# SPGSS1_1.0 register map
Vendor: Texas Instruments
Registers are 32-bit, read-write, no defined reset value unless marked. A register's access mark holds for its fields unless they carry their own. Offsets are as the file gives them; [hi:lo] are bit positions; lines under a group give offsets from that group; {n}, {i} and the like mark numbered series; 'fields as' and 'values as' point back to an identical list; <NAME> marks a mode.

## SPGSS1 (part 4 of 8)
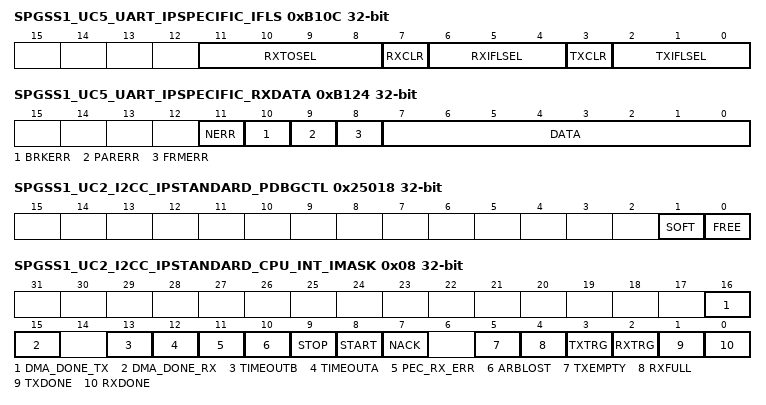
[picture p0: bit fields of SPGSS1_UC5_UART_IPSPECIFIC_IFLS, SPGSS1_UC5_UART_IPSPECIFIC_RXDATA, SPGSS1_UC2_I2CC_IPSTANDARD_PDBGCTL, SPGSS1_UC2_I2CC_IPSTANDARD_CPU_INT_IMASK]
0xB10C SPGSS1_UC5_UART_IPSPECIFIC_IFLS — UART Interrupt FIFO Level Select Register
  [11:8] RXTOSEL — UART Receive Interrupt Timeout Select. When receiving no start edge for an additional character within the set bittimes a RX interrupt is set even if the FIFO level is not reached. A value of 0 disables this function.
    0=MINIMUM (Smallest value); 15=MAXIMUM (Highest possible value)
  [7] RXCLR — RX FIFO CLEAR. Setting this bit will clear the RX FIFO contents.
    0=DISABLE (Disable FIFO clear); 1=ENABLE (Enable FIFO Clear)
  [6:4] RXIFLSEL — FIFO Level Select for generating events (interrupt/dma). Note: for undefined settings the default configuration is used.
    1=LVL_1_4 (RX FIFO >= 1/4 full); 2=LVL_1_2 (RX FIFO >= 1/2 full (default)); 3=LVL_3_4 (RX FIFO >= 3/4 full); 4=LVL_NOT_EMPTY (Opposite of empty); 5=LVL_FULL (RX FIFO is full); 6=LVL_ALMOST_FULL (RX_FIFO >= (MAX_FIFO_LEN -1)); 7=LVL_ALMOST_EMPTY (RX_FIFO <= 1)
  [3] TXCLR — TX FIFO CLEAR. Setting this bit will clear the TX FIFO contents.
    0=DISABLE (Disable FIFO clear); 1=ENABLE (Enable FIFO Clear)
  [2:0] TXIFLSEL — FIFO Level Select for generating events (interrupt/dma). Note: for undefined settings the default configuration is used.
    1=LVL_3_4 (TX FIFO <= 3/4 empty); 2=LVL_1_2 (TX FIFO <= 1/2 empty (default)); 3=LVL_1_4 (TX FIFO <= 1/4 empty); 4=LVL_NOT_FULL (Opposite of full); 5=LVL_EMPTY (TX FIFO is empty); 6=LVL_ALMOST_EMPTY (TX FIFO <= 1); 7=LVL_ALMOST_FULL (TX_FIFO >= (MAX_FIFO_LEN -1))
0xB110 SPGSS1_UC5_UART_IPSPECIFIC_IBRD — UART Integer Baud-Rate Divisor Register
  [15:0] DIVINT — Integer Baud-Rate Divisor
    0=MINIMUM (Smallest value); 0xFFFF=MAXIMUM (Highest possible value)
0xB114 SPGSS1_UC5_UART_IPSPECIFIC_FBRD — UART Fractional Baud-Rate Divisor Register
  [5:0] DIVFRAC — Fractional Baud-Rate Divisor
    0=MINIMUM (Smallest value); 63=MAXIMUM (Highest possible value)
0xB120 SPGSS1_UC5_UART_IPSPECIFIC_TXDATA — UART Transmit Data Register
  [7:0] DATA — Data Transmitted or Received Data that is to be transmitted via the UART is written to this field. When read, this field contains the data that was received by the UART.
    0=MINIMUM (Smallest value); 255=MAXIMUM (Highest possible value)
0xB124 SPGSS1_UC5_UART_IPSPECIFIC_RXDATA ro — UART Receive Data Register
  [11] NERR — Noise Error. Writing to this bit has no effect. The flag is cleared by writing 1 to the NERR bit in the UART EVENT ICLR register.
    0=CLR (No noise error occurred); 1=SET (Noise error occurred during majority voting)
  [10] BRKERR — UART Break Error Writing to this bit has no effect. The flag is cleared by writing 1 to the BRKERR bit in the UART EVENT ICLR register. This error is associated with the character at the top of the FIFO. When a break occurs, only one 0 character is loaded into the FIFO. The next character is only enabled after the receive data input goes to a 1 (marking state) and the next valid start bit is received.
    0=CLR (No break condition has occurred); 1=SET (A break condition has been detected, indicating that the receive data input was held low for longer than a full-word transmission time (defined as start, data, parity, and stop bits).)
  [9] PARERR — UART Parity Error Writing to this bit has no effect. The flag is cleared by writing 1 to the PARERR bit in the UART EVENT ICLR register.
    0=CLR (No parity error has occurred); 1=SET (The parity of the received data character does not match the parity defined by bits 2 and 7 of the UARTLCRH register.)
  [8] FRMERR — UART Framing Error Writing to this bit has no effect. The flag is cleared by writing 1 to the FRMERR bit in the UART EVENT ICLR register. This error is associated with the character at the top of the FIFO.
    0=CLR (No framing error has occurred); 1=SET (The received character does not have a valid stop bit sequence, which is one or two stop bits depending on the UARTLCRH.STP2 setting (a valid stop bit is 1).)
  [7:0] DATA — Received Data. When read, this field contains the data that was received by the UART.
    values as SPGSS1_UC5_UART_IPSPECIFIC_TXDATA.DATA
0xB148 SPGSS1_UC5_UART_IPSPECIFIC_AMASK — Self Address Mask Register
  [7:0] MSK — Self Address Mask for 9-Bit Mode This field contains the address mask that creates a set of addresses that should be matched. A 0 bit in the MSK bitfield configures, that the corresponding bit in the ADDR bitfield of the UARTxADDR register is don't care. A 1 bit in the MSK bitfield configures, that the corresponding bit in the ADDR bitfield of the UARTxADDR register must match.
    values as SPGSS1_UC5_UART_IPSPECIFIC_TXDATA.DATA
0xB14C SPGSS1_UC5_UART_IPSPECIFIC_ADDR — Self Address Register
  [7:0] ADDR — Self Address for 9-Bit Mode This field contains the address that should be matched when UARTxAMASK is FFh.
    values as SPGSS1_UC5_UART_IPSPECIFIC_TXDATA.DATA
0xBE00 SPGSS1_UC5_UART_LMGMT_DFT_ATRT_TEST0 — Test 0 register
  [4:0] DTB_MUX_SEL — This bit field is used to select DTB mux digital output signals.
    0=DISABLE (Disables DTB MUX); {v}=GRP{v} (Selects test group {v}) (v=1..7)
0x25000 SPGSS1_UC2_I2CC_IPSTANDARD_CLKDIV — Clock Divider
  [2:0] RATIO — Selects divide ratio of module clock Division factor 0 : DIV_BY_1 1 : DIV_BY_2 .... 63: DIV_BY_64
0x25008 SPGSS1_UC2_I2CC_IPSTANDARD_CLKSEL — Clock Select for Ultra Low Power peripherals
  [3] BUSCLK_SEL — Selects BUS CLK as clock source if enabled
    0=DISABLE (Does not select this clock as a source); 1=ENABLE (Select this clock as a source)
0x25018 SPGSS1_UC2_I2CC_IPSTANDARD_PDBGCTL — Peripheral Debug Control
  [1] SOFT — Soft halt boundary control. This function is only available, if [FREE] is set to 'STOP'
    0=DEPRECATED (Not supported); 1=DELAYED (The peripheral blocks the debug freeze until it has reached a boundary where it can resume without corruption)
  [0] FREE — Free run control
    0=STOP (The peripheral freezes functionality while the Core Halted input is asserted and resumes when it is deasserted.); 1=RUN (The peripheral ignores the state of the Core Halted input)
0x25020 SPGSS1_UC2_I2CC_IPSTANDARD_CPU_INT group
  0x00 SPGSS1_UC2_I2CC_IPSTANDARD_IIDX ro — Interrupt index
    [7:0] STAT — I2C Module Interrupt Vector Value. This register provides the highes priority interrupt index. A read clears the corresponding interrupt flag in RIS and MISC. 15h-1Fh = Reserved
      0=NO_INTR (No interrupt pending); 1=RXDONEFG (Data received); 2=TXDONEFG (data transmitted); 3=RXTRG (Receive Trigger); 4=TXTRG (Transmit Trigger); 5=RXFULL (RX FIFO FULL Event/interrupt pending); 6=TXEMPTY (Transmit FIFO/Buffer Empty Event/interrupt pending); 8=NACKFG (Address/Data NACK); 9=STARTFG (Start Event); 10=STOPFG (Stop Event); 11=ARBLOSTFG (Arbitration Lost); 12=PEC_RX_ERR (PEC Receive Error Event); 13=TIMEOUTA (Timeout A Event); 14=TIMEOUTB (Timeout B Event); 16=DMA_DONE_RX (DMA DONE on Channel RX); 17=DMA_DONE_TX (DMA DONE on Channel TX); 19=DMA_PREIRQ_RX (DMA PRE IRQ INTERRUPT); 20=DMA_PREIRQ_TX (DMA PRE IRQ INTERRUPT)
  0x08 SPGSS1_UC2_I2CC_IPSTANDARD_CPU_INT_IMASK — Interrupt mask
    [16] DMA_DONE_TX — DMA Done on Event Channel TX
      0=CLR (Interrupt disabled); 1=SET (Set Interrupt Mask)
    [15] DMA_DONE_RX — DMA Done on Event Channel RX
      0=CLR (Interrupt disabled); 1=SET (Set Interrupt Mask)
    [13] TIMEOUTB — Timeout B Interrupt
      0=CLR (Clear Interrupt Mask); 1=SET (Set Interrupt Mask)
    [12] TIMEOUTA — TIMEOUTA interrupt
      0=CLR (Clear Interrupt Mask); 1=SET (Set Interrupt Mask)
    [11] PEC_RX_ERR — RX Pec Error Interrupt
      0=CLR (Clear Interrupt Mask); 1=SET (Set Interrupt Mask)
    [10] ARBLOST — Arbitration Lost interrupt
      0=CLR (Clear Interrupt Mask); 1=SET (Set Interrupt Mask)
    [9] STOP — STOP interrupt
      0=CLR (Clear Interrupt Mask); 1=SET (Set Interrupt Mask)
    [8] START — START interrupt
      0=CLR (Clear Interrupt Mask); 1=SET (Set Interrupt Mask)
    [7] NACK — NACK interrupt
      0=CLR (Clear Interrupt Mask); 1=SET (Set Interrupt Mask)
    [5] TXEMPTY — Transmit FIFO/Buffer Empty interrupt.
      0=CLR (Clear Interrupt Mask); 1=SET (Set Interrupt Mask)
    [4] RXFULL — RXFIFO full event
      0=CLR (Clear Interrupt Mask); 1=SET (Set Interrupt Mask)
    [3] TXTRG — Transmit Trigger
      0=CLR (Clear Interrupt Mask); 1=SET (Set Interrupt Mask)
    [2] RXTRG — Receive Trigger
      0=CLR (Clear Interrupt Mask); 1=SET (Set Interrupt Mask)
    [1] TXDONE — Transmit Transaction completed Interrupt
      0=CLR (Clear Interrupt Mask); 1=SET (Set Interrupt Mask)
    [0] RXDONE — RXDONE interrupt
      0=CLR (Clear Interrupt Mask); 1=SET (Set Interrupt Mask)
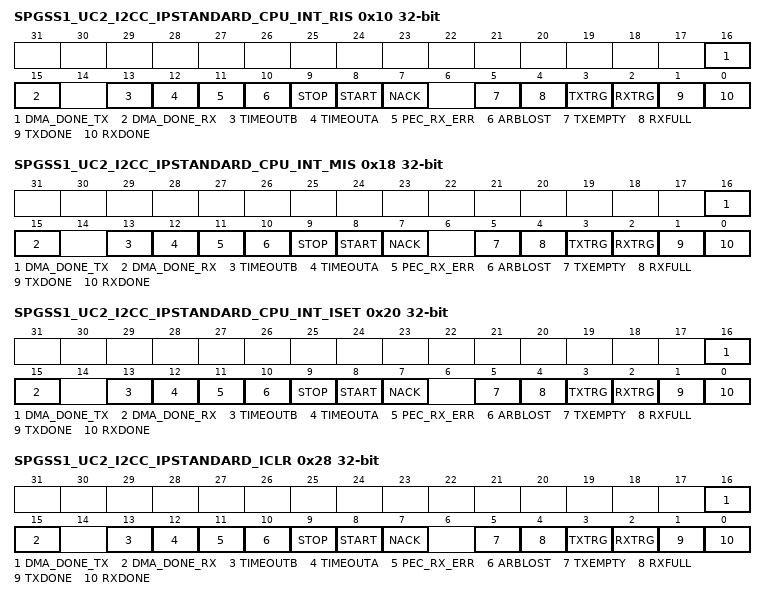
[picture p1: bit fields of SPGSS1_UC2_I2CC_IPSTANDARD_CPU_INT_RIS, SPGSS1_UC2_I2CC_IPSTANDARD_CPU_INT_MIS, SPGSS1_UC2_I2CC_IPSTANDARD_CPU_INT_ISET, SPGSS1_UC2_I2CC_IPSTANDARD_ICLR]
  0x10 SPGSS1_UC2_I2CC_IPSTANDARD_CPU_INT_RIS — Raw interrupt status
    [16] DMA_DONE_TX — DMA Done on Event Channel TX
      0=CLR (Interrupt disabled); 1=SET (Set Interrupt Mask)
    [15] DMA_DONE_RX — DMA Done on Event Channel RX
      0=CLR (Interrupt disabled); 1=SET (Set Interrupt Mask)
    [13] TIMEOUTB — Timeout B Interrupt
      0=CLR (Interrupt did not occur); 1=SET (Interrupt occured)
    [12] TIMEOUTA — Timeout A Interrupt
      0=CLR (Interrupt did not occur); 1=SET (Set Interrupt Mask)
    [11] PEC_RX_ERR — Receive PEC Error Interrupt: set when the calculated PEC does not match received PEC
      0=CLR (Interrupt did not occur); 1=SET (Interrupt Occured)
    [10] ARBLOST — Arbitration Lost Interrupt: in multi-controller systems, when this controller loses out during arbitration
      0=CLR (Interrupt did not occur); 1=SET (Set Interrupt Mask)
    [9] STOP — STOP Detection Interrupt
      0=CLR (Interrupt did not occur); 1=SET (Set Interrupt Mask)
    [8] START — START Detection Interrupt
      0=CLR (Interrupt did not occur); 1=SET (Set Interrupt Mask)
    [7] NACK — Address/Data NACK Interrupt: set when address or data nack is received
      0=CLR (Interrupt did not occur); 1=SET (Set Interrupt Mask)
    [5] TXEMPTY — Transmit FIFO Empty: set when Transmit FIFO is empty
      0=CLR (Interrupt did not occur); 1=SET (Interrupt occured)
    [4] RXFULL — RXFIFO full event. This interrupt is set when receive FIFO is full.
      0=CLR (Interrupt did not occur); 1=SET (Interrupt occured)
    [3] TXTRG — Transmit Trigger When FIFO is present, as per IFLS settings When FIFO is not present, trigger when transmit buffer is empty
      0=CLR (Clear Interrupt Mask); 1=SET (Set Interrupt Mask)
    [2] RXTRG — Receive Trigger When FIFO is present, as per IFLS settings when FIFO is not present, this indicates when buffer is full
      0=CLR (Clear Interrupt Mask); 1=SET (Set Interrupt Mask)
    [1] TXDONE — Transmit Done Interrupt: TXDONE interrupt is raised when a burst length completes Or, in case of quick command, when a quick command with R/Wn bit set to '0'
      0=CLR (Interrupt did not occur); 1=SET (Set Interrupt Mask)
    [0] RXDONE — Receive Done Interrupt: RXDONE interrupt is raised when a burst length completes Or, in case of quick command, when a quick command with R/Wn bit set to '1'
      0=CLR (Interrupt did not occur); 1=SET (Set Interrupt Mask)
  0x18 SPGSS1_UC2_I2CC_IPSTANDARD_CPU_INT_MIS — Masked interrupt status
    [16] DMA_DONE_TX — DMA Done on Event Channel TX
      0=CLR (Interrupt disabled); 1=SET (Set Interrupt Mask)
    [15] DMA_DONE_RX — DMA Done on Event Channel RX
      0=CLR (Interrupt disabled); 1=SET (Set Interrupt Mask)
    [13] TIMEOUTB — Timeout B Interrupt
      0=CLR (Clear interrupt mask); 1=SET (Set interrupt mask)
    [12] TIMEOUTA — Timeout A Interrupt
      0=CLR (Interrupt did not occur); 1=SET (Set Interrupt Mask)
    [11] PEC_RX_ERR — RX Pec Error Interrupt
      0=CLR (Clear interrupt mask); 1=SET (Set interrupt mask)
    [10] ARBLOST — Arbitration Lost Interrupt
      0=CLR (Interrupt did not occur); 1=SET (Set Interrupt Mask)
    [9] STOP — STOP Detection Interrupt
      0=CLR (Interrupt did not occur); 1=SET (Set Interrupt Mask)
    [8] START — START Detection Interrupt
      0=CLR (Interrupt did not occur); 1=SET (Set Interrupt Mask)
    [7] NACK — Address/Data NACK Interrupt
      0=CLR (Interrupt did not occur); 1=SET (Set Interrupt Mask)
    [5] TXEMPTY — Transmit FIFO Empty masked interrupt. This interrupt is set if all data in the Transmit FIFO have been shifted out and the transmit goes into idle mode.
      0=CLR (Interrupt did not occur); 1=SET (Interrupt occured)
    [4] RXFULL — Masked RXFIFO full event
      0=CLR (Interrupt did not occur); 1=SET (Interrupt occured)
    [3] TXTRG — Transmit Trigger
      0=CLR (Clear Interrupt Mask); 1=SET (Set Interrupt Mask)
    [2] RXTRG — Receive Trigger
      0=CLR (Clear Interrupt Mask); 1=SET (Set Interrupt Mask)
    [1] TXDONE — Transmit Transaction completed Interrupt
      0=CLR (Interrupt did not occur); 1=SET (Set Interrupt Mask)
    [0] RXDONE — Receive Data Interrupt
      0=CLR (Interrupt did not occur); 1=SET (Set Interrupt Mask)
  0x20 SPGSS1_UC2_I2CC_IPSTANDARD_CPU_INT_ISET — Interrupt set
    [16] DMA_DONE_TX — DMA Done on Event Channel TX
      0=NO_EFFECT (Interrupt disabled); 1=SET (Set Interrupt Mask)
    [15] DMA_DONE_RX — DMA Done on Event Channel RX
      0=NO_EFFECT (Interrupt disabled); 1=SET (Set Interrupt Mask)
    [13] TIMEOUTB — Timeout B Interrupt
      0=NO_EFFECT (Writing 0 has no effect); 1=SET (Set interrupt)
    [12] TIMEOUTA — Timeout A interrupt
      0=NO_EFFECT (Writing 0 has no effect); 1=SET (Set Interrupt Mask)
    [11] PEC_RX_ERR — RX Pec Error Interrupt
      0=NO_EFFECT (Writing 0 has no effect); 1=SET (Set interrupt)
    [10] ARBLOST — Arbitration Lost Interrupt
      values as TIMEOUTA
    [9] STOP — STOP Detection Interrupt
      values as TIMEOUTA
    [8] START — START Detection Interrupt
      values as TIMEOUTA
    [7] NACK — Address/Data NACK Interrupt
      values as TIMEOUTA
    [5] TXEMPTY — Transmit FIFO Empty interrupt mask. This interrupt is set if all data in the Transmit FIFO have been shifted out and the transmit goes into idle mode.
      0=NO_EFFECT (Writing 0 has no effect); 1=SET (Set Interrupt)
    [4] RXFULL — RXFIFO full event.
      0=NO_EFFECT (Writing 0 has no effect); 1=SET (Set Interrupt)
    [3] TXTRG — Transmit Trigger
      0=NO_EFFECT (Clear Interrupt Mask); 1=SET (Set Interrupt Mask)
    [2] RXTRG — Receive Trigger
      values as TXTRG
    [1] TXDONE — Transmit Transaction completed Interrupt
      values as TIMEOUTA
    [0] RXDONE — Receive Data Interrupt Signals that a byte has been received
      values as TIMEOUTA
  0x28 SPGSS1_UC2_I2CC_IPSTANDARD_ICLR — Interrupt clear
    [16] DMA_DONE_TX — DMA Done on Event Channel TX
      0=NO_EFFECT (Interrupt disabled); 1=CLR (Set Interrupt Mask)
    [15] DMA_DONE_RX — DMA Done on Event Channel RX
      0=NO_EFFECT (Interrupt disabled); 1=CLR (Set Interrupt Mask)
    [13] TIMEOUTB — Timeout B Interrupt
      0=NO_EFFECT (Writing 0 has no effect); 1=CLR (Clear Interrupt)
    [12] TIMEOUTA — Timeout A interrupt
      0=NO_EFFECT (Writing 0 has no effect); 1=CLR (Set Interrupt Mask)
    [11] PEC_RX_ERR — RX Pec Error Interrupt
      values as TIMEOUTB
    [10] ARBLOST — Arbitration Lost Interrupt
      values as TIMEOUTA
    [9] STOP — STOP Detection Interrupt
      values as TIMEOUTA
    [8] START — START Detection Interrupt
      values as TIMEOUTA
    [7] NACK — Address/Data NACK Interrupt
      values as TIMEOUTA
    [5] TXEMPTY — Transmit FIFO Empty interrupt mask. This interrupt is set if all data in the Transmit FIFO have been shifted out and the transmit goes into idle mode.
      values as TIMEOUTB
    [4] RXFULL — RXFIFO full event.
      values as TIMEOUTB
    [3] TXTRG — Transmit FIFO Trigger
      0=NO_EFFECT (Clear Interrupt Mask); 1=CLR (Set Interrupt Mask)
    [2] RXTRG — Receive Trigger
      values as TXTRG
    [1] TXDONE — Transmit Transaction completed Interrupt
      values as TIMEOUTA
    [0] RXDONE — Receive Data Interrupt Signals that a byte has been received
      values as TIMEOUTA
0x25050 SPGSS1_UC2_I2CC_IPSTANDARD_DMA_TRIG1 group
  0x08 SPGSS1_UC2_I2CC_IPSTANDARD_DMA_TRIG1_IMASK — Interrupt mask
    [2] RXTRG — Receive Trigger
      0=CLR (Clear Interrupt Mask); 1=SET (Set Interrupt Mask)
  0x10 SPGSS1_UC2_I2CC_IPSTANDARD_DMA_TRIG1_RIS — Raw interrupt status
    [2] RXTRG — Receive Trigger When FIFO is present, trigger when RX FIFO contains >= defined bytes when FIFO is not present, this indicates when buffer is full
      0=CLR (Clear Interrupt Mask); 1=SET (Set Interrupt Mask)
  0x18 SPGSS1_UC2_I2CC_IPSTANDARD_DMA_TRIG1_MIS — Masked interrupt status
    fields as SPGSS1_UC2_I2CC_IPSTANDARD_DMA_TRIG1.SPGSS1_UC2_I2CC_IPSTANDARD_DMA_TRIG1_IMASK
  0x20 SPGSS1_UC2_I2CC_IPSTANDARD_DMA_TRIG1_ISET — Interrupt set
    [2] RXTRG — Receive Trigger
      values as SPGSS1_UC2_I2CC_IPSTANDARD_CPU_INT.SPGSS1_UC2_I2CC_IPSTANDARD_CPU_INT_ISET.TXTRG
0x25080 SPGSS1_UC2_I2CC_IPSTANDARD_DMA_TRIG0 group
  0x08 SPGSS1_UC2_I2CC_IPSTANDARD_DMA_TRIG0_IMASK — Interrupt mask
    [3] TXTRG — Transmit Trigger
      0=CLR (Clear Interrupt Mask); 1=SET (Set Interrupt Mask)
  0x10 SPGSS1_UC2_I2CC_IPSTANDARD_DMA_TRIG0_RIS — Raw interrupt status
    fields as SPGSS1_UC2_I2CC_IPSTANDARD_DMA_TRIG0.SPGSS1_UC2_I2CC_IPSTANDARD_DMA_TRIG0_IMASK
  0x18 SPGSS1_UC2_I2CC_IPSTANDARD_DMA_TRIG0_MIS — Masked interrupt status
    fields as SPGSS1_UC2_I2CC_IPSTANDARD_DMA_TRIG0.SPGSS1_UC2_I2CC_IPSTANDARD_DMA_TRIG0_IMASK
  0x20 SPGSS1_UC2_I2CC_IPSTANDARD_DMA_TRIG0_ISET — Interrupt set
    [3] TXTRG — Transmit Trigger
      values as SPGSS1_UC2_I2CC_IPSTANDARD_CPU_INT.SPGSS1_UC2_I2CC_IPSTANDARD_CPU_INT_ISET.TXTRG
0x250E4 SPGSS1_UC2_I2CC_IPSTANDARD_INTCTL — Interrupt control register
  [0] INTEVAL — Writing a 1 to this field re-evaluates the interrupt sources.
    0=DISABLE (The interrupt or event line is disabled.); 1=EVAL (The interrupt or event line is in software mode. Software must clear the RIS.)
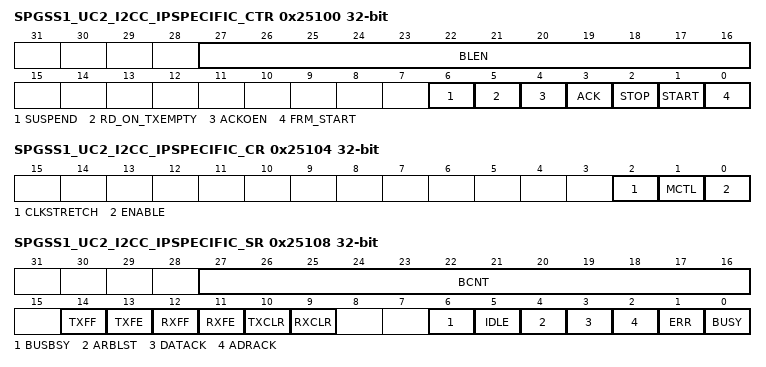
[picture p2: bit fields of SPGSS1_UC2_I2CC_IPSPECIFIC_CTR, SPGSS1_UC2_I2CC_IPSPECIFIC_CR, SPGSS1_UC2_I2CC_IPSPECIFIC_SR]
0x25100 SPGSS1_UC2_I2CC_IPSPECIFIC_CTR — Control Register
  [27:16] BLEN — I2C transaction length This field contains the programmed length of bytes of the Transaction.
    0=MINIMUM (Smallest value); 0xFFF=MAXIMUM (Highest possible value)
  [6] SUSPEND — Suspend external communication
    0=DISABLE (Functional mode resumed); 1=ENABLE (External communication suspended)
  [5] RD_ON_TXEMPTY — Read on TX Empty
    0=DISABLE (No special behavior); 1=ENABLE (When 1 the Controller will transmit all bytes from the TX FIFO before continuing with the programmed Burst Run Read. If the DIR is not set to Read in the MSA then this bit is ignored. The Start must be set in the MCTR for proper I2C protocol. The Controller will first send the Start Condition, I2C Address with R/W bit set to write, before sending the bytes in the TX FIFO. When the TX FIFO is empty, the I2C transaction will continue as programmed in MTCR and MSA without sending a Stop Condition. This is intended to be used to perform simple I2C command based reads transition that will complete after initiating them without having to get an interrupt to turn the bus around.)
  [4] ACKOEN — ACK overrride Enable
    0=DISABLE (No special behavior); 1=ENABLE (When 1 and the Controller is receiving data and the number of bytes indicated in MBLEN have been received, the state machine will generate an rxdone interrupt and wait at the start of the ACK for FW to indicate if an ACK or NACK should be sent. The ACK or NACK is selected by writing the MCTR register and setting ACK accordingly. The other fields in this register can also be written at this time to continue on with the transaction. If a NACK is sent the state machine will automatically send a Stop.)
  [3] ACK — Data Acknowledge Enable. Software needs to configure this bit to send the ACK or NACK. See field decoding in Table: MCTR Field decoding.
    0=DISABLE (The last received data byte of a transaction is not acknowledged automatically .); 1=ENABLE (The last received data byte of a transaction is acknowledged automatically .)
  [2] STOP — Generate STOP
    0=DISABLE (The controller does not generate the STOP condition.); 1=ENABLE (The controller generates the STOP condition. See field decoding in Table: MCTR Field decoding.)
  [1] START — Generate START
    0=DISABLE (The controller does not generate the START condition.); 1=ENABLE (The controller generates the START or repeated START condition. See field decoding in Table: MCTR Field decoding.)
  [0] FRM_START — Start Transfer
    0=DISABLE (In standard mode, this encoding means the Controller is unable to transmit or receive data.); 1=ENABLE (The Controller is able to transmit or receive data. See field decoding in Table: MCTR Field decoding.)
0x25104 SPGSS1_UC2_I2CC_IPSPECIFIC_CR — Configuration
  [2] CLKSTRETCH — Clock Stretching. This bit controls the support for clock stretching of the I2C bus.
    0=DISABLE (Disables the clock stretching detection. This can be disabled if no Target on the bus does support clock stretching, so that the maximum speed on the bus can be reached.); 1=ENABLE (Enables the clock stretching detection. Enabling the clock stretching ensures compliance to the I2C standard but could limit the speed due the clock stretching.)
  [1] MCTL — MultiController mode. In MultiController mode the SCL high time counts once the SCL line has been detected high. If this is not enabled the high time counts as soon as the SCL line has been set high by the I2C controller.
    0=DISABLE (Disable MultiController mode.); 1=ENABLE (Enable MultiController mode.)
  [0] ENABLE — Enable module. After this bit has been set, it should not be set again unless it has been cleared by writing a 0 or by a reset, otherwise transfer failures may occur.
    0=DISABLE (Disables operation.); 1=ENABLE (Enables operation.)
0x25108 SPGSS1_UC2_I2CC_IPSPECIFIC_SR ro — Status Register
  [27:16] BCNT — Transaction Count This field contains the current count-down value of the transaction.
    values as SPGSS1_UC2_I2CC_IPSPECIFIC_CTR.BLEN
  [14] TXFF — Transmit FIFO Full The meaning of this bit depends on the state of the FEN bit in the CTL0 register.
    0=CLEARED (The transmitter is not full.); 1=SET (If the FIFO is disabled (FEN is 0), the transmit holding register is full. If the FIFO is enabled (FEN is 1), the transmit FIFO is full.)
  [13] TXFE — Transmit FIFO Empty The meaning of this bit depends on the state of the FEN bit in the CTL0 register.
    0=CLEARED (The transmitter has data to transmit.); 1=SET (If the FIFO is disabled (FEN is 0), the transmit holding register is empty. If the FIFO is enabled (FEN is 1), the transmit FIFO is empty.)
  [12] RXFF — Receive FIFO Full The meaning of this bit depends on the state of the FEN bit in the CTL0 register.
    0=CLEARED (The receiver can receive data.); 1=SET (If the FIFO is disabled (FEN is 0), the receive holding register is full. If the FIFO is enabled (FEN is 1), the receive FIFO is full.)
  [11] RXFE — Receive FIFO Empty The meaning of this bit depends on the state of the FEN bit in the CTL0 register.
    0=CLEARED (The receiver is not empty.); 1=SET (If the FIFO is disabled (FEN is 0), the receive holding register is empty. If the FIFO is enabled (FEN is 1), the receive FIFO is empty.)
  [10] TXCLR — TX FIFO Clear Status
    0=CLEARED (FIFO is not cleared); 1=SET (FIFO clear is complete)
  [9] RXCLR — RX FIFO Clear Status
    values as TXCLR
  [6] BUSBSY — I2C Bus is Busy Controller State Machine will wait until this bit to be cleared before starting a transaction. When first enabling the Controller in multi Controller environments, FW should wait for one I2C clock period after setting ACTIVE high before writing to the CTR register to start the transaction so that if SCL goes low it will trigger the BUSBSY.
    0=CLEARED (The I2C bus is idle.); 1=SET ('This Status bit is set on a START or when SCL goes low. It is cleared on a STOP, or when a SCL high bus busy timeout occurs and SCL and SDA are both high. This status is cleared when the ACTIVE bit is low. Note that the Controller State Machine will wait until this bit is cleared before starting an I2C transaction. When first enabling the Controller in multi Controller environments, FW should wait for one I2C clock period after setting ACTIVE high before writing to the MTCR register to start the transaction so that if SCL goes low it will trigger the BUSBSY.)
  [5] IDLE — I2C Idle
    0=CLEARED (The I2C controller is not idle.); 1=SET (The I2C controller is idle.)
  [4] ARBLST — Arbitration Lost
    0=CLEARED (The I2C controller won arbitration.); 1=SET (The I2C controller lost arbitration.)
  [3] DATACK — Acknowledge Data
    0=CLEARED (The transmitted data was acknowledged); 1=SET (The transmitted data was not acknowledged.)
  [2] ADRACK — Acknowledge Address
    0=CLEARED (The transmitted address was acknowledged); 1=SET (The transmitted address was not acknowledged.)
  [1] ERR — Error The error can be from the Target address not being acknowledged or the transmit data not being acknowledged.
    0=CLEARED (No error was detected on the last operation.); 1=SET (An error occurred on the last operation.)
  [0] BUSY — FSM Busy The BUSY bit is set during an ongoing transaction, so is set during the transmit/receive of the amount of data set in MBLEN including START, RESTART, Address and STOP signal generation when required for the current transaction.
    0=CLEARED (The controller is idle.); 1=SET (The controller is busy.)
